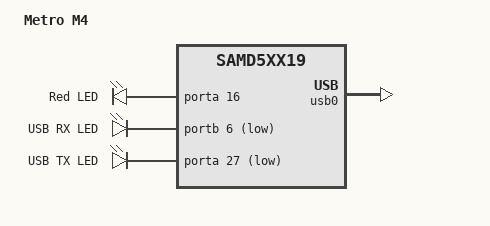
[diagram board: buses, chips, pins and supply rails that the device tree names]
/*
 * Copyright (c) 2019 Benjamin Valentin
 * Copyright (c) 2025 Brian Tate
 *
 * SPDX-License-Identifier: Apache-2.0
 */

/dts-v1/;
#include <atmel/samd5xx19.dtsi>
#include "metro_m4-pinctrl.dtsi"
#include <zephyr/dt-bindings/input/input-event-codes.h>

/ {
	model = "Metro M4";
	compatible = "adafruit,metro-m4";

	chosen {
		zephyr,console = &sercom3;
		zephyr,shell-uart = &sercom3;
		zephyr,sram = &sram0;
		zephyr,flash = &flash0;
	};

	/* These aliases are provided for compatibility with samples */
	aliases {
		led-red = &led_red;
		led-rx = &led_rx;
		led-tx = &led_tx;
//		neopixel-led = &neopixel_led0; //ToDo: look into this
	};

	leds {
		compatible = "gpio-leds";
		led_red: led_red {
			gpios = <&porta 16 GPIO_ACTIVE_HIGH>;
			label = "Red LED";
		};
		led_rx: led_rx {
			gpios = <&portb 6 GPIO_ACTIVE_LOW>;
			label = "USB RX LED";
		};
		led_tx: led_tx {
			gpios = <&porta 27 GPIO_ACTIVE_LOW>;
			label = "USB TX LED";
		};
	};
};

&cpu0 {
	clock-frequency = <120000000>;
};



zephyr_udc0: &usb0 {
	status = "okay";

	pinctrl-0 = <&usb_dc_default>;
	pinctrl-names = "default";
};

//ToDo: What is this for?
&flash0 {
	partitions {
		compatible = "fixed-partitions";
		#address-cells = <1>;
		#size-cells = <1>;

		/*
		 * The final 16 KiB is reserved for the application.
		 * Storage partition will be used by FCB/LittleFS/NVS
		 * if enabled.
		 */
		storage_partition: partition@fc000 {
			label = "storage";
			reg = <0x000fc000 0x00004000>;
		};
	};
};

//ToDo: add QSPI flash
